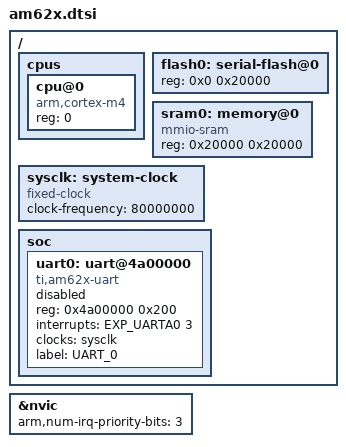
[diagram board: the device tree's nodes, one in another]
/* SPDX-License-Identifier: Apache-2.0 */

#include <arm/armv7-m.dtsi>

#include <mem.h>
#include <zephyr/dt-bindings/i2c/i2c.h>
#include <zephyr/dt-bindings/gpio/gpio.h>

#define INT_UARTA0              21          // UART0 Rx and Tx  //Not sure about this

/* Note: Zephyr uses exception numbers, vs the IRQ */
/* which are offset by 16: */
#define EXP_UARTA0 (INT_UARTA0 - 16)    //Not sure about this

/ {
        cpus {
                #address-cells = <1>;
                #size-cells = <0>;

                cpu@0 {
                        device_type = "cpu";
                        compatible = "arm,cortex-m4";
                        reg = <0>;
                };
        };


	flash0: serial-flash@0 {
		reg = <0x0 0x20000>;
	};

	sram0: memory@0 {
		compatible = "mmio-sram"; //Not sure about this
		reg = <0x20000 0x20000>;
	};

        sysclk: system-clock {
                compatible = "fixed-clock";
                clock-frequency = <80000000>;
                #clock-cells = <0>;
        };

        soc {
                uart0: uart@4a00000 {
                        compatible = "ti,am62x-uart";
                        reg = <0x4a00000 0x200>;
                        interrupts = <EXP_UARTA0 3>;
                        clocks = <&sysclk>;
                        status = "disabled";
                        label = "UART_0";
                };

        };
};

&nvic {
        arm,num-irq-priority-bits = <3>;
};
